# STM32F446ZET7 register map
File version: 1.0
Registers are 32-bit, access not given, reset 0x0 unless marked. A register's access mark holds for its fields unless they carry their own. Offsets are from the block's base; [hi:lo] are bit positions; {n}, {i} and the like mark numbered series.

## RCC
Base 0x40023800
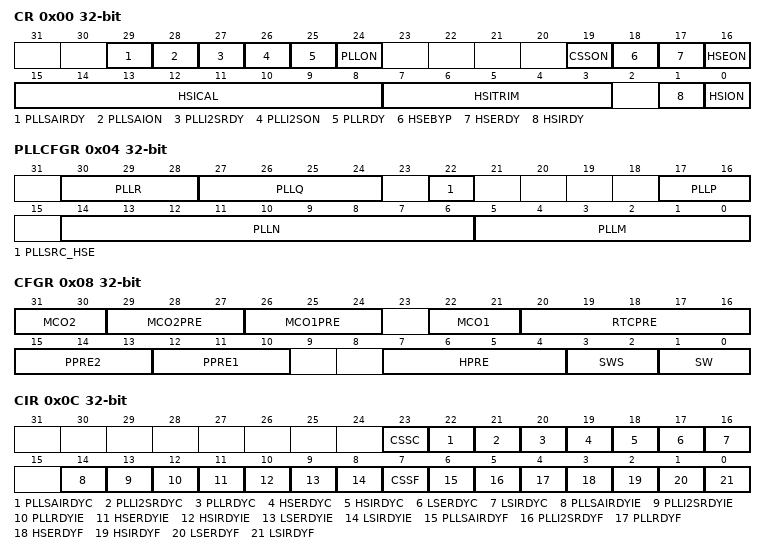
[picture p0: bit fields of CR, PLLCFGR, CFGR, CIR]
0x00 CR
  [29] PLLSAIRDY, [28] PLLSAION, [27] PLLI2SRDY, [26] PLLI2SON, [25] PLLRDY, [24] PLLON, [19] CSSON, [18] HSEBYP, [17] HSERDY, [16] HSEON, [15:8] HSICAL, [7:3] HSITRIM, [1] HSIRDY, [0] HSION
0x04 PLLCFGR
  [30:28] PLLR, [27:24] PLLQ, [22] PLLSRC_HSE, [17:16] PLLP, [14:6] PLLN, [5:0] PLLM
0x08 CFGR
  [31:30] MCO2, [29:27] MCO2PRE, [26:24] MCO1PRE, [22:21] MCO1, [20:16] RTCPRE, [15:13] PPRE2, [12:10] PPRE1, [7:4] HPRE, [3:2] SWS, [1:0] SW
0x0C CIR
  [23] CSSC, [22] PLLSAIRDYC, [21] PLLI2SRDYC, [20] PLLRDYC, [19] HSERDYC, [18] HSIRDYC, [17] LSERDYC, [16] LSIRDYC, [14] PLLSAIRDYIE, [13] PLLI2SRDYIE, [12] PLLRDYIE, [11] HSERDYIE, [10] HSIRDYIE, [9] LSERDYIE, [8] LSIRDYIE, [7] CSSF, [6] PLLSAIRDYF, [5] PLLI2SRDYF, [4] PLLRDYF, [3] HSERDYF, [2] HSIRDYF, [1] LSERDYF, [0] LSIRDYF
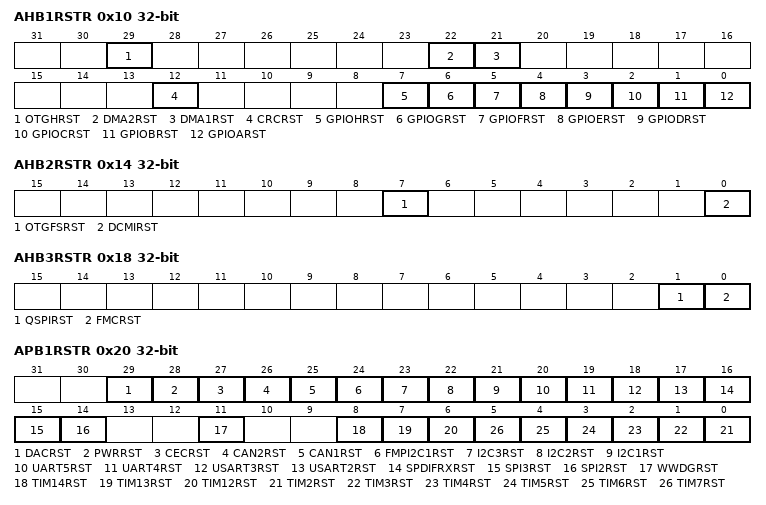
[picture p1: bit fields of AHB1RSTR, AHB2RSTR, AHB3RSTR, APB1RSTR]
0x10 AHB1RSTR
  [29] OTGHRST, [22] DMA2RST, [21] DMA1RST, [12] CRCRST, [7] GPIOHRST, [6] GPIOGRST, [5] GPIOFRST, [4] GPIOERST, [3] GPIODRST, [2] GPIOCRST, [1] GPIOBRST, [0] GPIOARST
0x14 AHB2RSTR
  [7] OTGFSRST, [0] DCMIRST
0x18 AHB3RSTR
  [1] QSPIRST, [0] FMCRST
0x20 APB1RSTR
  [29] DACRST, [28] PWRRST, [27] CECRST, [26] CAN2RST, [25] CAN1RST, [24] FMPI2C1RST, [23] I2C3RST, [22] I2C2RST, [21] I2C1RST, [20] UART5RST, [19] UART4RST, [18] USART3RST, [17] USART2RST, [16] SPDIFRXRST, [15] SPI3RST, [14] SPI2RST, [11] WWDGRST, [8] TIM14RST, [7] TIM13RST, [6] TIM12RST, [n-2] TIM{n}RST (n=2..7)
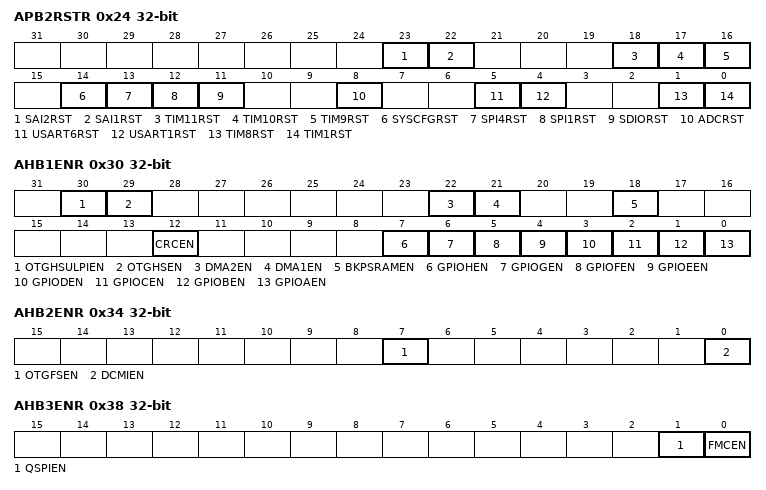
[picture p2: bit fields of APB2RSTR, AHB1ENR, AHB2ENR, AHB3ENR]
0x24 APB2RSTR
  [23] SAI2RST, [22] SAI1RST, [18] TIM11RST, [17] TIM10RST, [16] TIM9RST, [14] SYSCFGRST, [13] SPI4RST, [12] SPI1RST, [11] SDIORST, [8] ADCRST, [5] USART6RST, [4] USART1RST, [1] TIM8RST, [0] TIM1RST
0x30 AHB1ENR
  [30] OTGHSULPIEN, [29] OTGHSEN, [22] DMA2EN, [21] DMA1EN, [18] BKPSRAMEN, [12] CRCEN, [7] GPIOHEN, [6] GPIOGEN, [5] GPIOFEN, [4] GPIOEEN, [3] GPIODEN, [2] GPIOCEN, [1] GPIOBEN, [0] GPIOAEN
0x34 AHB2ENR
  [7] OTGFSEN, [0] DCMIEN
0x38 AHB3ENR
  [1] QSPIEN, [0] FMCEN
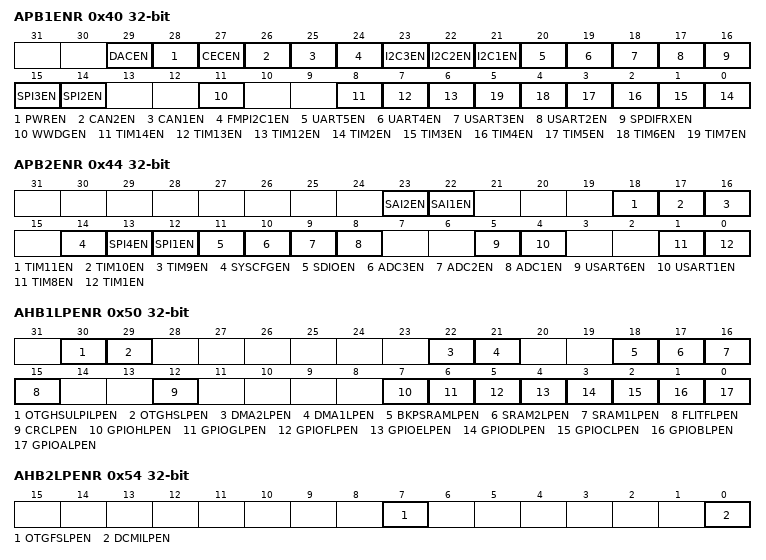
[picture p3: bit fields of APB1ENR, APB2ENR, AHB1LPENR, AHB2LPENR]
0x40 APB1ENR
  [29] DACEN, [28] PWREN, [27] CECEN, [26] CAN2EN, [25] CAN1EN, [24] FMPI2C1EN, [23] I2C3EN, [22] I2C2EN, [21] I2C1EN, [20] UART5EN, [19] UART4EN, [18] USART3EN, [17] USART2EN, [16] SPDIFRXEN, [15] SPI3EN, [14] SPI2EN, [11] WWDGEN, [8] TIM14EN, [7] TIM13EN, [6] TIM12EN, [n-2] TIM{n}EN (n=2..7)
0x44 APB2ENR
  [23] SAI2EN, [22] SAI1EN, [18] TIM11EN, [17] TIM10EN, [16] TIM9EN, [14] SYSCFGEN, [13] SPI4EN, [12] SPI1EN, [11] SDIOEN, [10] ADC3EN, [9] ADC2EN, [8] ADC1EN, [5] USART6EN, [4] USART1EN, [1] TIM8EN, [0] TIM1EN
0x50 AHB1LPENR
  [30] OTGHSULPILPEN, [29] OTGHSLPEN, [22] DMA2LPEN, [21] DMA1LPEN, [18] BKPSRAMLPEN, [17] SRAM2LPEN, [16] SRAM1LPEN, [15] FLITFLPEN, [12] CRCLPEN, [7] GPIOHLPEN, [6] GPIOGLPEN, [5] GPIOFLPEN, [4] GPIOELPEN, [3] GPIODLPEN, [2] GPIOCLPEN, [1] GPIOBLPEN, [0] GPIOALPEN
0x54 AHB2LPENR
  [7] OTGFSLPEN, [0] DCMILPEN
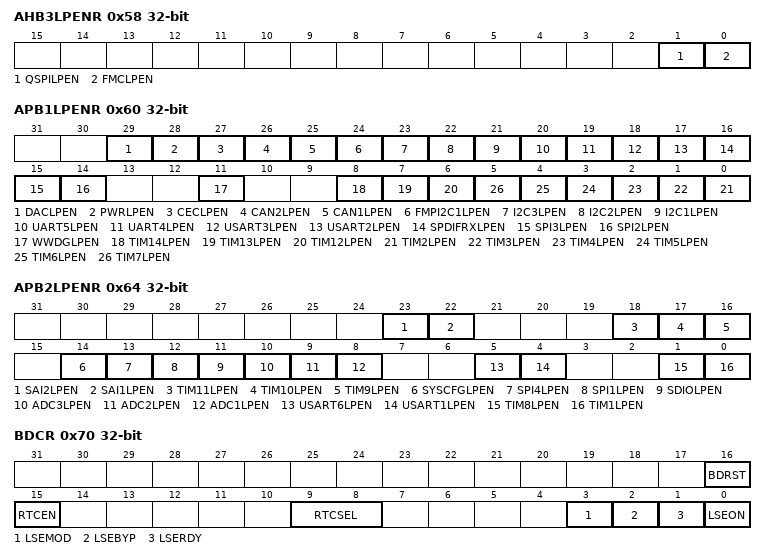
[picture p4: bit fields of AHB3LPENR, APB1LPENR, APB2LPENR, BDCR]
0x58 AHB3LPENR
  [1] QSPILPEN, [0] FMCLPEN
0x60 APB1LPENR
  [29] DACLPEN, [28] PWRLPEN, [27] CECLPEN, [26] CAN2LPEN, [25] CAN1LPEN, [24] FMPI2C1LPEN, [23] I2C3LPEN, [22] I2C2LPEN, [21] I2C1LPEN, [20] UART5LPEN, [19] UART4LPEN, [18] USART3LPEN, [17] USART2LPEN, [16] SPDIFRXLPEN, [15] SPI3LPEN, [14] SPI2LPEN, [11] WWDGLPEN, [8] TIM14LPEN, [7] TIM13LPEN, [6] TIM12LPEN, [n-2] TIM{n}LPEN (n=2..7)
0x64 APB2LPENR
  [23] SAI2LPEN, [22] SAI1LPEN, [18] TIM11LPEN, [17] TIM10LPEN, [16] TIM9LPEN, [14] SYSCFGLPEN, [13] SPI4LPEN, [12] SPI1LPEN, [11] SDIOLPEN, [10] ADC3LPEN, [9] ADC2LPEN, [8] ADC1LPEN, [5] USART6LPEN, [4] USART1LPEN, [1] TIM8LPEN, [0] TIM1LPEN
0x70 BDCR
  [16] BDRST, [15] RTCEN, [9:8] RTCSEL, [3] LSEMOD, [2] LSEBYP, [1] LSERDY, [0] LSEON
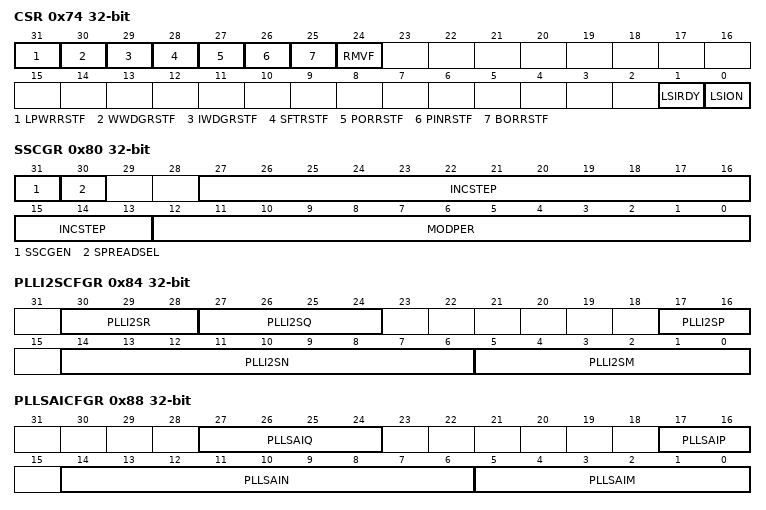
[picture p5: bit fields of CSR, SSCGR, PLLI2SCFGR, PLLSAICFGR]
0x74 CSR
  [31] LPWRRSTF, [30] WWDGRSTF, [29] IWDGRSTF, [28] SFTRSTF, [27] PORRSTF, [26] PINRSTF, [25] BORRSTF, [24] RMVF, [1] LSIRDY, [0] LSION
0x80 SSCGR
  [31] SSCGEN, [30] SPREADSEL, [27:13] INCSTEP, [12:0] MODPER
0x84 PLLI2SCFGR
  [30:28] PLLI2SR, [27:24] PLLI2SQ, [17:16] PLLI2SP, [14:6] PLLI2SN, [5:0] PLLI2SM
0x88 PLLSAICFGR
  [27:24] PLLSAIQ, [17:16] PLLSAIP, [14:6] PLLSAIN, [5:0] PLLSAIM
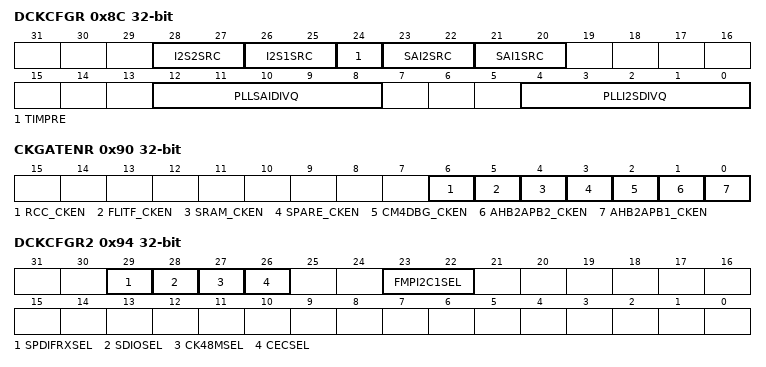
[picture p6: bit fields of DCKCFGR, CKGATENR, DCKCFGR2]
0x8C DCKCFGR
  [28:27] I2S2SRC, [26:25] I2S1SRC, [24] TIMPRE, [23:22] SAI2SRC, [21:20] SAI1SRC, [12:8] PLLSAIDIVQ, [4:0] PLLI2SDIVQ
0x90 CKGATENR
  [6] RCC_CKEN, [5] FLITF_CKEN, [4] SRAM_CKEN, [3] SPARE_CKEN, [2] CM4DBG_CKEN, [1] AHB2APB2_CKEN, [0] AHB2APB1_CKEN
0x94 DCKCFGR2
  [29] SPDIFRXSEL, [28] SDIOSEL, [27] CK48MSEL, [26] CECSEL, [23:22] FMPI2C1SEL
